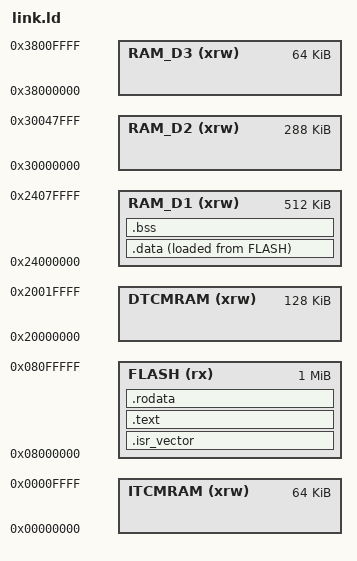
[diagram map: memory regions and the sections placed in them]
ENTRY(Reset_Handler)

MEMORY
{
  RAM_D1 (xrw)   : ORIGIN = 0x24000000, LENGTH =  512K
  FLASH   (rx)   : ORIGIN = 0x08000000, LENGTH = 1024K
  DTCMRAM (xrw)  : ORIGIN = 0x20000000, LENGTH = 128K
  RAM_D2 (xrw)   : ORIGIN = 0x30000000, LENGTH = 288K
  RAM_D3 (xrw)   : ORIGIN = 0x38000000, LENGTH = 64K
  ITCMRAM (xrw)  : ORIGIN = 0x00000000, LENGTH = 64K
}

SECTIONS
{
  .isr_vector :
  {
    KEEP(*(.isr_vector))
  } >FLASH

  .text :
  {
    *(.text)
    *(.text*)
  } >FLASH

  .rodata :
  {
    *(.rodata)
    *(.rodata*)
  } >FLASH

  .data :
  {
    _sdata = .;
    *(.data)
    *(.data*)
    _edata = .;
  } >RAM_D1 AT> FLASH

  .bss :
  {
    _sbss = .;
    *(.bss)
    *(.bss*)
    _ebss = .;
    _end = .;
  } >RAM_D1

  _sidata = LOADADDR(.data);
  _estack = ORIGIN(RAM_D1) + LENGTH(RAM_D1);

  /DISCARD/ :
  {
    libc.a ( * )
    libm.a ( * )
    libgcc.a ( * )
  }
}
